# STM32H723VEH6 register map
File version: 1.0
Registers are 32-bit, access not given, reset 0x0 unless marked. A register's access mark holds for its fields unless they carry their own. Offsets are from the block's base; [hi:lo] are bit positions.

## SPDIFRX1
Base 0x40004000
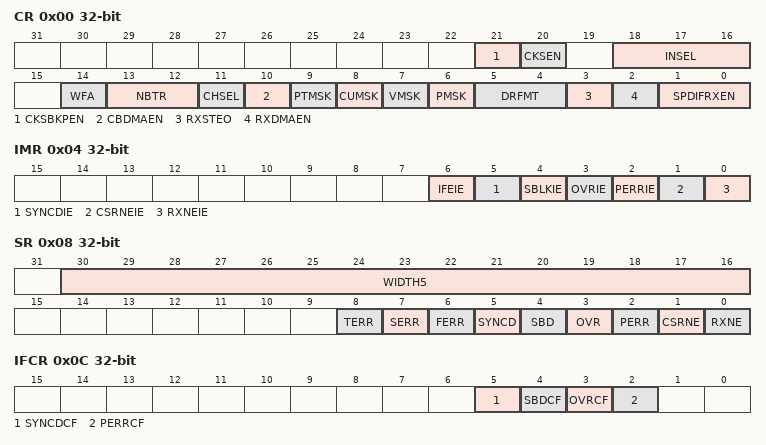
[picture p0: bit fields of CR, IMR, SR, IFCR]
0x00 CR
  [21] CKSBKPEN, [20] CKSEN, [18:16] INSEL, [14] WFA, [13:12] NBTR, [11] CHSEL, [10] CBDMAEN, [9] PTMSK, [8] CUMSK, [7] VMSK, [6] PMSK, [5:4] DRFMT, [3] RXSTEO, [2] RXDMAEN, [1:0] SPDIFRXEN
0x04 IMR
  [6] IFEIE, [5] SYNCDIE, [4] SBLKIE, [3] OVRIE, [2] PERRIE, [1] CSRNEIE, [0] RXNEIE
0x08 SR
  [30:16] WIDTH5, [8] TERR, [7] SERR, [6] FERR, [5] SYNCD, [4] SBD, [3] OVR, [2] PERR, [1] CSRNE, [0] RXNE
0x0C IFCR
  [5] SYNCDCF, [4] SBDCF, [3] OVRCF, [2] PERRCF
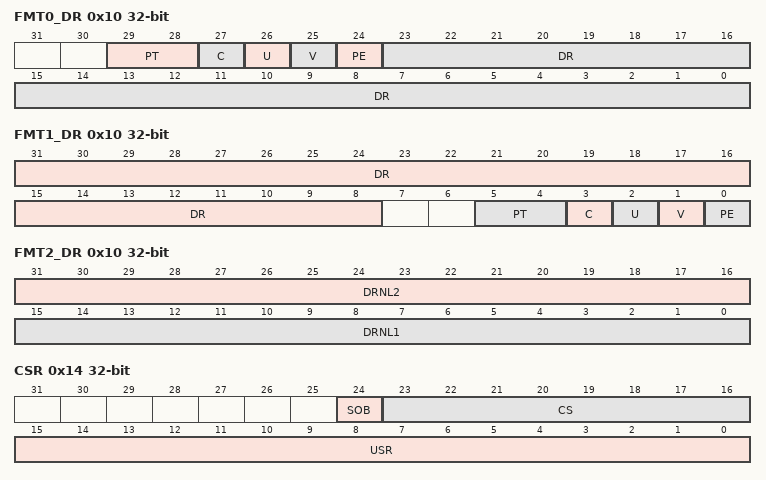
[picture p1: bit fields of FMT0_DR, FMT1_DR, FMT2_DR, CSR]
0x10 FMT0_DR
  [29:28] PT, [27] C, [26] U, [25] V, [24] PE, [23:0] DR
0x10 FMT1_DR
  [31:8] DR, [5:4] PT, [3] C, [2] U, [1] V, [0] PE
0x10 FMT2_DR
  [31:16] DRNL2, [15:0] DRNL1
0x14 CSR
  [24] SOB, [23:16] CS, [15:0] USR
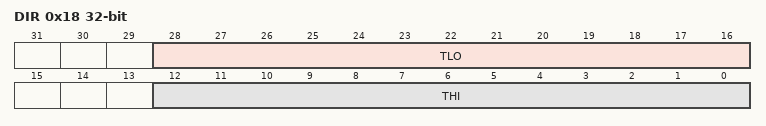
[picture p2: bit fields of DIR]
0x18 DIR
  [28:16] TLO, [12:0] THI

## USART2
Base 0x40004400
Same registers: USART3 0x40004800, UART4 0x40004C00, UART5 0x40005000, UART7 0x40007800, UART8 0x40007C00, USART1 0x40011000, USART6 0x40011400, UART9 0x40011800, USART10 0x40011C00
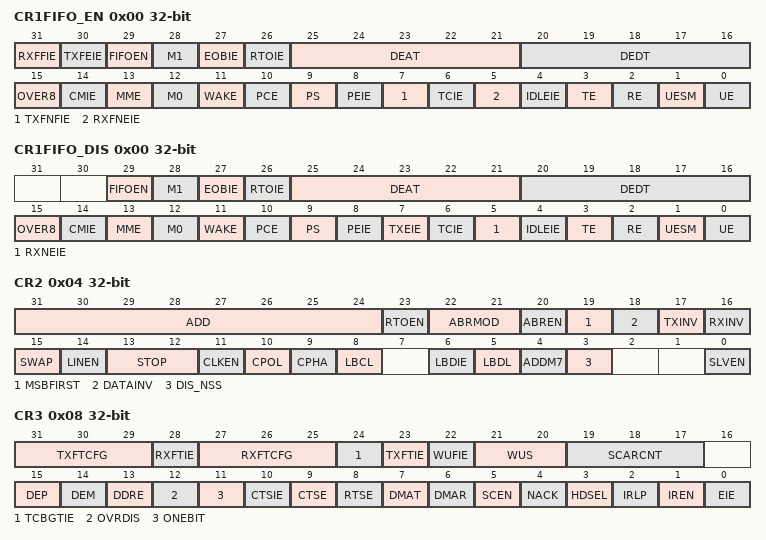
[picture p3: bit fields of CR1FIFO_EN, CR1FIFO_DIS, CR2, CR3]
0x00 CR1FIFO_EN
  [31] RXFFIE, [30] TXFEIE, [29] FIFOEN, [28] M1, [27] EOBIE, [26] RTOIE, [25:21] DEAT, [20:16] DEDT, [15] OVER8, [14] CMIE, [13] MME, [12] M0, [11] WAKE, [10] PCE, [9] PS, [8] PEIE, [7] TXFNFIE, [6] TCIE, [5] RXFNEIE, [4] IDLEIE, [3] TE, [2] RE, [1] UESM, [0] UE
0x00 CR1FIFO_DIS
  [29] FIFOEN, [28] M1, [27] EOBIE, [26] RTOIE, [25:21] DEAT, [20:16] DEDT, [15] OVER8, [14] CMIE, [13] MME, [12] M0, [11] WAKE, [10] PCE, [9] PS, [8] PEIE, [7] TXEIE, [6] TCIE, [5] RXNEIE, [4] IDLEIE, [3] TE, [2] RE, [1] UESM, [0] UE
0x04 CR2
  [31:24] ADD, [23] RTOEN, [22:21] ABRMOD, [20] ABREN, [19] MSBFIRST, [18] DATAINV, [17] TXINV, [16] RXINV, [15] SWAP, [14] LINEN, [13:12] STOP, [11] CLKEN, [10] CPOL, [9] CPHA, [8] LBCL, [6] LBDIE, [5] LBDL, [4] ADDM7, [3] DIS_NSS, [0] SLVEN
0x08 CR3
  [31:29] TXFTCFG, [28] RXFTIE, [27:25] RXFTCFG, [24] TCBGTIE, [23] TXFTIE, [22] WUFIE, [21:20] WUS, [19:17] SCARCNT, [15] DEP, [14] DEM, [13] DDRE, [12] OVRDIS, [11] ONEBIT, [10] CTSIE, [9] CTSE, [8] RTSE, [7] DMAT, [6] DMAR, [5] SCEN, [4] NACK, [3] HDSEL, [2] IRLP, [1] IREN, [0] EIE
0x0C BRR
  [15:0] BRR
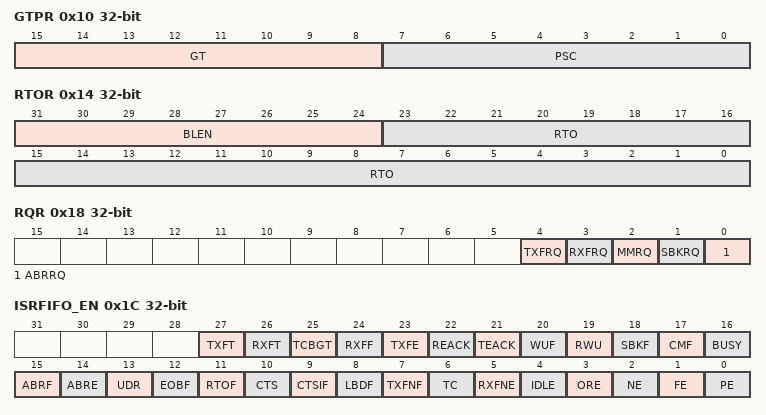
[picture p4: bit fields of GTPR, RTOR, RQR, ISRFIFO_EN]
0x10 GTPR
  [15:8] GT, [7:0] PSC
0x14 RTOR
  [31:24] BLEN, [23:0] RTO
0x18 RQR
  [4] TXFRQ, [3] RXFRQ, [2] MMRQ, [1] SBKRQ, [0] ABRRQ
0x1C ISRFIFO_EN
  [27] TXFT, [26] RXFT, [25] TCBGT, [24] RXFF, [23] TXFE, [22] REACK, [21] TEACK, [20] WUF, [19] RWU, [18] SBKF, [17] CMF, [16] BUSY, [15] ABRF, [14] ABRE, [13] UDR, [12] EOBF, [11] RTOF, [10] CTS, [9] CTSIF, [8] LBDF, [7] TXFNF, [6] TC, [5] RXFNE, [4] IDLE, [3] ORE, [2] NE, [1] FE, [0] PE
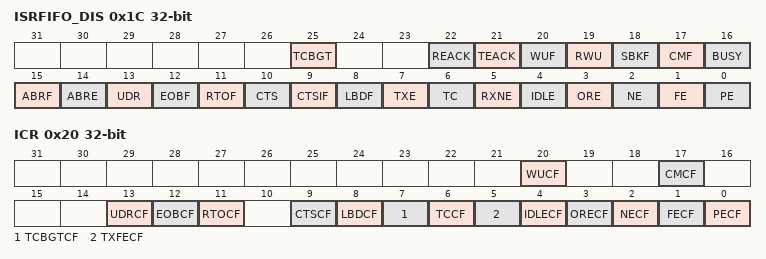
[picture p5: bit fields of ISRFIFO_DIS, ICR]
0x1C ISRFIFO_DIS
  [25] TCBGT, [22] REACK, [21] TEACK, [20] WUF, [19] RWU, [18] SBKF, [17] CMF, [16] BUSY, [15] ABRF, [14] ABRE, [13] UDR, [12] EOBF, [11] RTOF, [10] CTS, [9] CTSIF, [8] LBDF, [7] TXE, [6] TC, [5] RXNE, [4] IDLE, [3] ORE, [2] NE, [1] FE, [0] PE
0x20 ICR
  [20] WUCF, [17] CMCF, [13] UDRCF, [12] EOBCF, [11] RTOCF, [9] CTSCF, [8] LBDCF, [7] TCBGTCF, [6] TCCF, [5] TXFECF, [4] IDLECF, [3] ORECF, [2] NECF, [1] FECF, [0] PECF
0x24 RDR
  [8:0] RDR
0x28 TDR
  [8:0] TDR
0x2C PRESC
  [3:0] PRESCALER

## I2C1
Base 0x40005400
Same registers: I2C2 0x40005800, I2C3 0x40005C00, I2C5 0x40006400, I2C4 0x58001C00
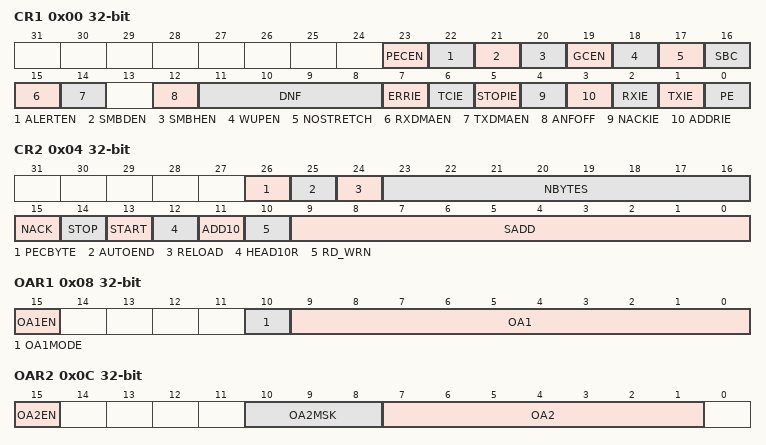
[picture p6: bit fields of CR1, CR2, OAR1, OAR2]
0x00 CR1
  [23] PECEN, [22] ALERTEN, [21] SMBDEN, [20] SMBHEN, [19] GCEN, [18] WUPEN, [17] NOSTRETCH, [16] SBC, [15] RXDMAEN, [14] TXDMAEN, [12] ANFOFF, [11:8] DNF, [7] ERRIE, [6] TCIE, [5] STOPIE, [4] NACKIE, [3] ADDRIE, [2] RXIE, [1] TXIE, [0] PE
0x04 CR2
  [26] PECBYTE, [25] AUTOEND, [24] RELOAD, [23:16] NBYTES, [15] NACK, [14] STOP, [13] START, [12] HEAD10R, [11] ADD10, [10] RD_WRN, [9:0] SADD
0x08 OAR1
  [15] OA1EN, [10] OA1MODE, [9:0] OA1
0x0C OAR2
  [15] OA2EN, [10:8] OA2MSK, [7:1] OA2
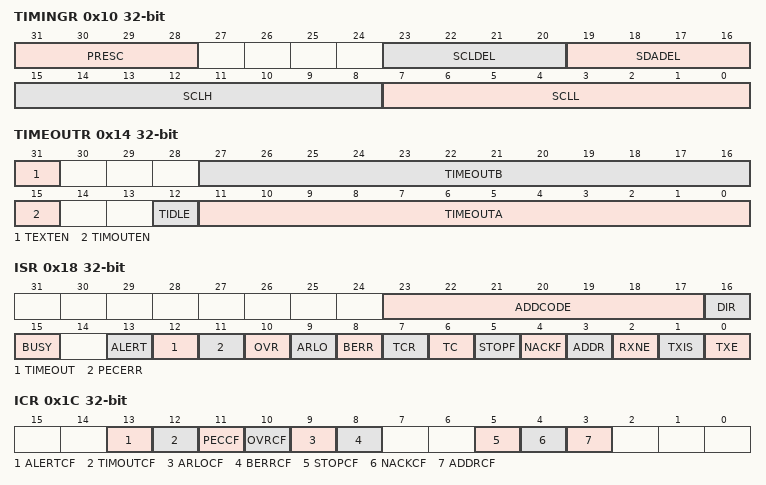
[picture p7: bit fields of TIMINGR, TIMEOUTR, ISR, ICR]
0x10 TIMINGR
  [31:28] PRESC, [23:20] SCLDEL, [19:16] SDADEL, [15:8] SCLH, [7:0] SCLL
0x14 TIMEOUTR
  [31] TEXTEN, [27:16] TIMEOUTB, [15] TIMOUTEN, [12] TIDLE, [11:0] TIMEOUTA
0x18 ISR
  [23:17] ADDCODE, [16] DIR, [15] BUSY, [13] ALERT, [12] TIMEOUT, [11] PECERR, [10] OVR, [9] ARLO, [8] BERR, [7] TCR, [6] TC, [5] STOPF, [4] NACKF, [3] ADDR, [2] RXNE, [1] TXIS, [0] TXE
0x1C ICR
  [13] ALERTCF, [12] TIMOUTCF, [11] PECCF, [10] OVRCF, [9] ARLOCF, [8] BERRCF, [5] STOPCF, [4] NACKCF, [3] ADDRCF
0x20 PECR
  [7:0] PEC
0x24 RXDR
  [7:0] RXDATA
0x28 TXDR
  [7:0] TXDATA
